AUTOSAR XML (schema 4-2-1)
standard types defined: float32, float64, sint8, sint16, sint32, uint8, uint16, uint32, boolean, dtRef_VOID, UInt8, Float32, Boolean, UInt32, SInt8
package /FoundationPkg/FoundationArchitecturePkg
  client server interface iElectricDriveControl
    operation enable
    operation getEnableState
      5 x arg, all with direction=OUT:
        state: type=tEnableState
        bridge1Health: type=tHealthStatus
        bridge2Health: type=tHealthStatus
        maxTimeCapability: type=tMaxTimeCapability
        redundancyLevel: type=tRedundancyLevel
    operation disable
  constant specification iTorqueChannelData_Channel{1..3}_Data_Init: value-spec={short-label=iTorqueChannelData_Channel{1..3}_Data_Init, fields=[0 Nm, 0]}
  sender receiver interface iTorqueChannelData
    data Channel{1..3}_Data: sw-calibration-access=READ-ONLY, type=tTorqueChannel, init-value=constant-reference=iTorqueChannelData_Channel{1..3}_Data_Init
  client server interface iElectricDrive
    5 x operation:
      setMotorTorqueDemand
        arg torque: type=tElectricMotorTorque, direction=IN
      getMotorTorqueEstimate
        arg torque: type=tElectricMotorTorque, direction=OUT
      getMotorMechanicalPosition
        arg position: type=tMechanicalMotorPosition, direction=OUT
      getMotorMechanicalVelocity
        arg velocity: type=tMechanicalMotorVelocity, direction=OUT
      getMotorTorqueDemand
        arg torque: type=tElectricMotorTorque, direction=OUT
  constant specification iAssistCapability_Capability_Init: value-spec={short-label=iAssistCapability_Capability_Init, fields=[0 %, 0 %]}
  sender receiver interface iAssistCapability
    data Capability: sw-calibration-access=READ-ONLY, type=tAssistCapability, init-value=constant-reference=iAssistCapability_Capability_Init
  constant specification iAssistTorque_AssistanceTorque_Init: value-spec={short-label=iAssistTorque_AssistanceTorque_Init, fields=[0 Nm, 0]}
  sender receiver interface iAssistTorque
    data AssistanceTorque: sw-calibration-access=READ-ONLY, type=tAssistTorque, init-value=constant-reference=iAssistTorque_AssistanceTorque_Init
  constant specification iVehicleData_VehicleSpeed_Init: value-spec={short-label=iVehicleData_VehicleSpeed_Init, fields=[0 Kph, 0, 0]}
  constant specification iVehicleData_EstimatedSteeringPosition_Init: value-spec={short-label=iVehicleData_EstimatedSteeringPosition_Init, fields=[0 deg, 0, 0 %]}
  constant specification iVehicleData_YawRate_Init: value-spec={short-label=iVehicleData_YawRate_Init, fields=[0 deg/S, 0]}
  sender receiver interface iVehicleData
    data VehicleSpeed: sw-calibration-access=READ-ONLY, type=tVehicleSpd, init-value=constant-reference=iVehicleData_VehicleSpeed_Init
    data EstimatedSteeringPosition: sw-calibration-access=READ-ONLY, type=tEstimatedSteeringPosition, init-value=constant-reference=iVehicleData_EstimatedSteeringPosition_Init
    data YawRate: sw-calibration-access=READ-ONLY, type=tYawRateData, init-value=constant-reference=iVehicleData_YawRate_Init
  constant specification iInputTorqueDemands_OverlayTorqueDemand_Init: value-spec={short-label=iInputTorqueDemands_OverlayTorqueDemand_Init, fields=[0 Nm, 0 Nm/s, 0, {short-label=tInputTorque_EQf_Init, fields=[1, 1, 1, 1]}]}
  constant specification iInputTorqueDemands_LimitingTorqueDemand_Init: value-spec={short-label=iInputTorqueDemands_LimitingTorqueDemand_Init, fields=[0 Nm, 0]}
  sender receiver interface iInputTorqueDemands
    data OverlayTorqueDemand: sw-calibration-access=READ-ONLY, type=tInputTorque, init-value=constant-reference=iInputTorqueDemands_OverlayTorqueDemand_Init
    data LimitingTorqueDemand: sw-calibration-access=READ-ONLY, type=tAssistTorque, init-value=constant-reference=iInputTorqueDemands_LimitingTorqueDemand_Init
package /FoundationPkg/FoundationArchitecturePkg/FoundationEpsAbstractionPkg
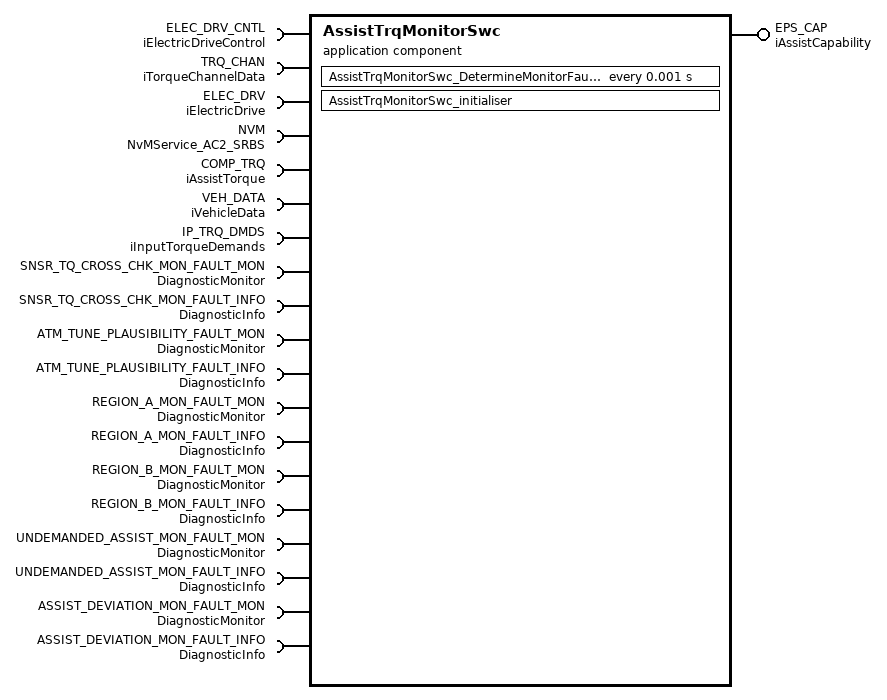
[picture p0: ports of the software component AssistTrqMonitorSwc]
  application sw component type AssistTrqMonitorSwc  # The AssistTrqMonitor reads the inputs and outputs of the main torque loop, and applies independent analysis of these signals in order to check that various ASIL D hazards are not present. If a hazard condition is detected the electric drive is disabled, and a fault is raised.
    4 x require port:
      ELEC_DRV_CNTL: required-interface=iElectricDriveControl
      TRQ_CHAN: required-interface=iTorqueChannelData  # The torque values read from each of the monitored channels
        required-com-specs:
          data-element=Channel{1..3}_Data, init-value=constant-reference=iTorqueChannelData_Channel{1..3}_Data_Init
      ELEC_DRV: required-interface=iElectricDrive
      NVM: required-interface=NvMService_AC2_SRBS  # Access to NVM
    provide port EPS_CAP: nonqueued-sender-com-spec{data-element=Capability, init-value=constant-reference=iAssistCapability_Capability_Init}, provided-interface=iAssistCapability  # The EPS assist capability, as a result of EPS diagnostic monitoring
    15 x require port:
      COMP_TRQ: nonqueued-receiver-com-spec{data-element=AssistanceTorque, init-value=constant-reference=iAssistTorque_AssistanceTorque_Init}, required-interface=iAssistTorque  # Compensated Torque input
      VEH_DATA: required-interface=iVehicleData  # Data regarding the vehicle dynamic state (speed, steering angle derived from the wheel speeds etc).
        required-com-specs:
          data-element=VehicleSpeed, init-value=constant-reference=iVehicleData_VehicleSpeed_Init
          data-element=EstimatedSteeringPosition, init-value=constant-reference=iVehicleData_EstimatedSteeringPosition_Init
          data-element=YawRate, init-value=constant-reference=iVehicleData_YawRate_Init
      IP_TRQ_DMDS: required-interface=iInputTorqueDemands
        required-com-specs:
          data-element=OverlayTorqueDemand, init-value=constant-reference=iInputTorqueDemands_OverlayTorqueDemand_Init
          data-element=LimitingTorqueDemand, init-value=constant-reference=iInputTorqueDemands_LimitingTorqueDemand_Init
      SNSR_TQ_CROSS_CHK_MON_FAULT_MON: required-interface=DiagnosticMonitor
      SNSR_TQ_CROSS_CHK_MON_FAULT_INFO: required-interface=DiagnosticInfo
      ATM_TUNE_PLAUSIBILITY_FAULT_MON: required-interface=DiagnosticMonitor
      ATM_TUNE_PLAUSIBILITY_FAULT_INFO: required-interface=DiagnosticInfo
      REGION_A_MON_FAULT_MON: required-interface=DiagnosticMonitor
      REGION_A_MON_FAULT_INFO: required-interface=DiagnosticInfo
      REGION_B_MON_FAULT_MON: required-interface=DiagnosticMonitor
      REGION_B_MON_FAULT_INFO: required-interface=DiagnosticInfo
      UNDEMANDED_ASSIST_MON_FAULT_MON: required-interface=DiagnosticMonitor
      UNDEMANDED_ASSIST_MON_FAULT_INFO: required-interface=DiagnosticInfo
      ASSIST_DEVIATION_MON_FAULT_MON: required-interface=DiagnosticMonitor
      ASSIST_DEVIATION_MON_FAULT_INFO: required-interface=DiagnosticInfo
    behavior AssistTrqMonitorSwc_IB: data-type-mapping=MappingSet, handle-termination-and-restart=NO-SUPPORT
      ar-typed-per-instance-memorys:
        data AssistTrqMonitorNvm: category=STRUCTURE, sw-calibration-access=READ-ONLY, type=tAssistTrqMonitorNvm
      timing event Event_DetermineMonitorFault: start-on-event=AssistTrqMonitorSwc_DetermineMonitorFault, period=0.001
      init event Event_initialiser_Init: start-on-event=AssistTrqMonitorSwc_initialiser
      implicit-inter-runnable-variables:
        data TunePlausibilityQf: sw-calibration-access=READ-ONLY, type=tQualityFactor, init-value=constant-reference=AssistTrqMonitorSwc_TunePlausibilityQf_Init  # This IRV is intended to inform the cyclic runnable that the plausibility fault is detected. In this case the cyclic runnable will set the capability to 0.
      per-instance-parameters:
        25 x parameter data prototype:
          ATM_COL_TQ_IDLE_THD: category=VALUE, sw-addr-method=VehicleTune, sw-calibration-access=READ-WRITE, type=Nm_0_0_to_2_0, init-value=constant-reference=VehicleTune_ATM_COL_TQ_IDLE_THD_Init  # Column Torque Idle Threshold
          ATM_UNDEMANDED_ASSI_SFTY_THD_MAP: category=ARRAY, sw-addr-method=VehicleTune, sw-calibration-access=READ-WRITE, type=tAtmUndemandedAssiSfbMap_0_0_to_255_0, init-value=constant-reference=VehicleTune_ATM_UNDEMANDED_ASSI_SFTY_THD_MAP_Init  # Assistance Torque Demand Safety Threshold for the detection of undemanded assist.
          ATM_ASSIST_CRV_MAP: category=ARRAY, sw-addr-method=VehicleTune, sw-calibration-access=READ-WRITE, type=tAtmAssistCrvMap_0_0_to_255_0, init-value=constant-reference=VehicleTune_ATM_ASSIST_CRV_MAP_Init  # Monitor Assist Curve Map which enables to determine the current assist torque capabilty with a certain additional Column Torque.
          ATM_ASSIST_CRV_MAP_BRKPTS: category=ARRAY, sw-addr-method=VehicleTune, sw-calibration-access=READ-WRITE, type=tAtmMonitorAssistCrvColTrqBpts_0_0_to_10_0, init-value=constant-reference=VehicleTune_ATM_ASSIST_CRV_MAP_BRKPTS_Init  # Column Torque Breakpoints for the Monitor Assist Curve Map.
          ATM_DRVR_TQ_SFTY_THD: category=VALUE, sw-addr-method=VehicleTune, sw-calibration-access=READ-WRITE, type=Nm_0_0_to_10_0, init-value=constant-reference=VehicleTune_ATM_DRVR_TQ_SFTY_THD_Init  # Driver Torque Safety Threshold
          ATM_DEB_RST_CNTR_THD: category=VALUE, sw-addr-method=VehicleTune, sw-calibration-access=READ-WRITE, type=ms_0_to_1000, init-value=constant-reference=VehicleTune_ATM_DEB_RST_CNTR_THD_Init  # Debounce Reset First Counter Threshold
          ATM_REGION_A_SFTY_THD_MAP: category=ARRAY, sw-addr-method=VehicleTune, sw-calibration-access=READ-WRITE, type=tAtmRegionASfbMap_0_0_to_255_0, init-value=constant-reference=VehicleTune_ATM_REGION_A_SFTY_THD_MAP_Init  # Region A Safety Threshold Map which provides an Assistance Torque Threshold above which a safety violation is detected.
          ATM_REGION_A_SFTY_THD_MAP_BRKPTS: category=ARRAY, sw-addr-method=VehicleTune, sw-calibration-access=READ-WRITE, type=tAtmRegionASfbMapBkpts_0_0_to_10_0, init-value=constant-reference=VehicleTune_ATM_REGION_A_SFTY_THD_MAP_BRKPTS_Init  # Column Torque Breakpoints for the Region A Safety Threshold Map.
          ATM_REGION_B_SFTY_THD_MAP: category=ARRAY, sw-addr-method=VehicleTune, sw-calibration-access=READ-WRITE, type=tAtmRegionBSfbMap_n255_0_to_255_0, init-value=constant-reference=VehicleTune_ATM_REGION_B_SFTY_THD_MAP_Init  # Region B Safety Threshold Map which provides an Assistance Torque Threshold above which a safety violation is detected.
          ATM_REGION_B_SFTY_THD_MAP_BRKPTS: category=ARRAY, sw-addr-method=VehicleTune, sw-calibration-access=READ-WRITE, type=tAtmRegionBSfbMapBkpts_0_0_to_10_0, init-value=constant-reference=VehicleTune_ATM_REGION_B_SFTY_THD_MAP_BRKPTS_Init  # Column Torque Breakpoints for the Region B Safety Threshold Map.
          ATM_SNSR_TQ_DE_THD: category=VALUE, sw-addr-method=VehicleTune, sw-calibration-access=READ-WRITE, type=Nm_0_0_to_10_0, init-value=constant-reference=VehicleTune_ATM_SNSR_TQ_DE_THD_Init  # Sensor Torque Deviation Threshold
          ATM_UNDEMANDED_TRIG_CNTR_THD: category=VALUE, sw-addr-method=VehicleTune, sw-calibration-access=READ-WRITE, type=ms_0_to_1000, init-value=constant-reference=VehicleTune_ATM_UNDEMANDED_TRIG_CNTR_THD_Init  # Debounce Counter for the undemanded assist fault Debouncer. If this failure situation is present for this duration the failure reaction will be triggered.
          ATM_VEH_SPD_BRKPTS: category=ARRAY, sw-addr-method=VehicleTune, sw-calibration-access=READ-WRITE, type=tAtmVehSpdMapBkpts_0_0_to_255_0, init-value=constant-reference=VehicleTune_ATM_VEH_SPD_BRKPTS_Init  # Vehicle Speed Breakpoints to be used for Assist Torque Monitor Safety Thresholds.
          ATM_ASSIST_DEVIATION_TRIG_CNTR_THD: category=VALUE, sw-addr-method=VehicleTune, sw-calibration-access=READ-WRITE, type=ms_0_to_1000, init-value=constant-reference=VehicleTune_ATM_ASSIST_DEVIATION_TRIG_CNTR_THD_Init  # Debounce Counter for the assist deviation fault debouncer. If this failure situation is present for this duration the failure reaction will be triggered.
          ATM_REGION_A_TRIG_CNTR_THD: category=VALUE, sw-addr-method=VehicleTune, sw-calibration-access=READ-WRITE, type=ms_0_to_1000, init-value=constant-reference=VehicleTune_ATM_REGION_A_TRIG_CNTR_THD_Init  # Debounce Counter for the region A fault debouncer. If this failure situation is present for this duration the failure reaction will be triggered.
          ATM_REGION_B_TRIG_CNTR_THD: category=VALUE, sw-addr-method=VehicleTune, sw-calibration-access=READ-WRITE, type=ms_0_to_1000, init-value=constant-reference=VehicleTune_ATM_REGION_B_TRIG_CNTR_THD_Init  # Debounce Counter for the region B fault debouncer. If this failure situation is present for this duration the failure reaction will be triggered.
          ATM_TQ_SNSR_ERR_TRIG_CNTR_THD: category=VALUE, sw-addr-method=VehicleTune, sw-calibration-access=READ-WRITE, type=ms_0_to_1000, init-value=constant-reference=VehicleTune_ATM_TQ_SNSR_ERR_TRIG_CNTR_THD_Init  # Debounce Counter for the torque sensor error fault debouncer. If this failure situation is present for this duration the failure reaction will be triggered.
          ATM_TQ_SNSR_CH_DE_TRIG_CNTR_THD: category=VALUE, sw-addr-method=VehicleTune, sw-calibration-access=READ-WRITE, type=ms_0_to_1000, init-value=constant-reference=VehicleTune_ATM_TQ_SNSR_CH_DE_TRIG_CNTR_THD_Init  # Debounce Counter for the torque sensor channel deviation fault debouncer. If this failure situation is present for this duration the failure reaction will be triggered.
          ATM_MAX_DEB_CNTR_VAL: category=VALUE, sw-addr-method=VehicleTune, sw-calibration-access=READ-WRITE, type=ms_0_to_1000, init-value=constant-reference=VehicleTune_ATM_MAX_DEB_CNTR_VAL_Init  # Maximum value of the ATM fault debounce counter
          ATM_DFT_VEH_SPD: category=VALUE, sw-addr-method=VehicleTune, sw-calibration-access=READ-WRITE, type=Kph_0_0_to_255_0, init-value=constant-reference=VehicleTune_ATM_DFT_VEH_SPD_Init  # ATM fallback vehicle speed to be used in case of unavailable filtered vehicle speed.
          ATM_RECIPR_GEAR_RATIO: category=VALUE, sw-addr-method=GearTune, sw-calibration-access=READ-WRITE, type=Float32_0_033_to_0_066, init-value=constant-reference=GearTune_ATM_RECIPR_GEAR_RATIO_Init  # Reciprocal Gear Ratio
          ATM_RECIPR_GEAR_EFFICIENCY: category=VALUE, sw-addr-method=GearTune, sw-calibration-access=READ-WRITE, type=Float32_1_0_to_2_0, init-value=constant-reference=GearTune_ATM_RECIPR_GEAR_EFFICIENCY_Init  # Reciprocal Gearbox Efficiency
          ATM_GEAR_POLARITY: category=VALUE, sw-addr-method=GearTune, sw-calibration-access=READ-WRITE, type=SInt8_n1_to_1, init-value=constant-reference=GearTune_ATM_GEAR_POLARITY_Init
          ATM_CHANNEL_HIGH_PRIORITY: category=ARRAY, sw-addr-method=SensorTune, sw-calibration-access=READ-WRITE, type=tTqSensChanHighPri, init-value=constant-reference=SensorTune_ATM_CHANNEL_HIGH_PRIORITY_Init  # Set which torque sensor channels are preferred during the torque calculation; some channels of the sensor can have cross chatter which disturbs the signal TRUE = High priority (preferable) FALSE = Low priority
          AssistTrqMonitorNvm_DEFAULT_VALUE: category=RECORD, type=tAssistTrqMonitorNvm, init-value=constant-reference=AssistTrqMonitorSwc_AssistTrqMonitorNvm_Init
      runnable AssistTrqMonitorSwc_DetermineMonitorFault: symbol=AssistTrqMonitor_DetermineMonitorFault  # Execute hazard detection functions for the controller torque assist path. Raise faults, disable electric drive and set zero EPS capability on fault detection. This is a diverse implementation of the main torque loop. It calculates Motor Torque Demand from the input torque signals, and then compares this with the Motor Torque Demand being requested by the main torque loop. The comparison must match within certain calibrated boundaries, and if not, a fault is raised and the motor drive is disabled. External torque demands which feed into the main loop, are compensated for by a torque signal which is subtracted from the requested Motor Torque Demand, before comparison.
        data-read-access:
          6 x access:
            R_TRQ_CHAN_Channel{1..3}_Data: accessed-variable=TRQ_CHAN.Channel{1..3}_Data
            R_COMP_TRQ_AssistanceTorque: accessed-variable=COMP_TRQ.AssistanceTorque
            R_VEH_DATA_VehicleSpeed: accessed-variable=VEH_DATA.VehicleSpeed
            R_IP_TRQ_DMDS_OverlayTorqueDemand: accessed-variable=IP_TRQ_DMDS.OverlayTorqueDemand
        data-write-access:
          access W_EPS_CAP_Capability: accessed-variable=EPS_CAP.Capability
        24 x parameter access:
          ATM_COL_TQ_IDLE_THD: accessed-parameter=ATM_COL_TQ_IDLE_THD
          ATM_DEB_RST_CNTR_THD: accessed-parameter=ATM_DEB_RST_CNTR_THD
          ATM_UNDEMANDED_TRIG_CNTR_THD: accessed-parameter=ATM_UNDEMANDED_TRIG_CNTR_THD
          ATM_ASSIST_CRV_MAP: accessed-parameter=ATM_ASSIST_CRV_MAP
          ATM_ASSIST_CRV_MAP_BRKPTS: accessed-parameter=ATM_ASSIST_CRV_MAP_BRKPTS
          ATM_DRVR_TQ_SFTY_THD: accessed-parameter=ATM_DRVR_TQ_SFTY_THD
          ATM_REGION_A_SFTY_THD_MAP: accessed-parameter=ATM_REGION_A_SFTY_THD_MAP
          ATM_REGION_A_SFTY_THD_MAP_BRKPTS: accessed-parameter=ATM_REGION_A_SFTY_THD_MAP_BRKPTS
          ATM_REGION_B_SFTY_THD_MAP: accessed-parameter=ATM_REGION_B_SFTY_THD_MAP
          ATM_REGION_B_SFTY_THD_MAP_BRKPTS: accessed-parameter=ATM_REGION_B_SFTY_THD_MAP_BRKPTS
          ATM_SNSR_TQ_DE_THD: accessed-parameter=ATM_SNSR_TQ_DE_THD
          ATM_UNDEMANDED_ASSI_SFTY_THD_MAP: accessed-parameter=ATM_UNDEMANDED_ASSI_SFTY_THD_MAP
          ATM_GEAR_POLARITY: accessed-parameter=ATM_GEAR_POLARITY
          ATM_RECIPR_GEAR_EFFICIENCY: accessed-parameter=ATM_RECIPR_GEAR_EFFICIENCY
          ATM_RECIPR_GEAR_RATIO: accessed-parameter=ATM_RECIPR_GEAR_RATIO
          ATM_VEH_SPD_BRKPTS: accessed-parameter=ATM_VEH_SPD_BRKPTS
          ATM_ASSIST_DEVIATION_TRIG_CNTR_THD: accessed-parameter=ATM_ASSIST_DEVIATION_TRIG_CNTR_THD
          ATM_REGION_A_TRIG_CNTR_THD: accessed-parameter=ATM_REGION_A_TRIG_CNTR_THD
          ATM_REGION_B_TRIG_CNTR_THD: accessed-parameter=ATM_REGION_B_TRIG_CNTR_THD
          ATM_TQ_SNSR_ERR_TRIG_CNTR_THD: accessed-parameter=ATM_TQ_SNSR_ERR_TRIG_CNTR_THD
          ATM_TQ_SNSR_CH_DE_TRIG_CNTR_THD: accessed-parameter=ATM_TQ_SNSR_CH_DE_TRIG_CNTR_THD
          ATM_MAX_DEB_CNTR_VAL: accessed-parameter=ATM_MAX_DEB_CNTR_VAL
          ATM_DFT_VEH_SPD: accessed-parameter=ATM_DFT_VEH_SPD
          ATM_CHANNEL_HIGH_PRIORITY: accessed-parameter=ATM_CHANNEL_HIGH_PRIORITY
        read-local-variables:
          access RV_TunePlausibilityQf: accessed-variable=TunePlausibilityQf
        23 x sync call, all with timeout=0:
          Call_ELEC_DRV_CNTL_disable: operation=ELEC_DRV_CNTL.disable
          Call_ELEC_DRV_getMotorTorqueDemand: operation=ELEC_DRV.getMotorTorqueDemand
          Call_REGION_A_MON_FAULT_SetEventStatus: operation=REGION_A_MON_FAULT_MON.SetEventStatus
          Call_REGION_A_MON_FAULT_ResetEventStatus: operation=REGION_A_MON_FAULT_MON.ResetEventDebounceStatus
          Call_REGION_A_MON_FAULT_GetEventStatus: operation=REGION_A_MON_FAULT_INFO.GetEventStatus
          Call_REGION_A_MON_FAULT_GetEventFailed: operation=REGION_A_MON_FAULT_INFO.GetEventFailed
          Call_REGION_B_MON_FAULT_SetEventStatus: operation=REGION_B_MON_FAULT_MON.SetEventStatus
          Call_REGION_B_MON_FAULT_ResetEventStatus: operation=REGION_B_MON_FAULT_MON.ResetEventDebounceStatus
          Call_REGION_B_MON_FAULT_GetEventStatus: operation=REGION_B_MON_FAULT_INFO.GetEventStatus
          Call_REGION_B_MON_FAULT_GetEventFailed: operation=REGION_B_MON_FAULT_INFO.GetEventFailed
          Call_ASSIST_DEVIATION_MON_FAULT_SetEventStatus: operation=ASSIST_DEVIATION_MON_FAULT_MON.SetEventStatus
          Call_ASSIST_DEVIATION_MON_FAULT_ResetEventStatus: operation=ASSIST_DEVIATION_MON_FAULT_MON.ResetEventDebounceStatus
          Call_ASSIST_DEVIATION_MON_FAULT_GetEventStatus: operation=ASSIST_DEVIATION_MON_FAULT_INFO.GetEventStatus
          Call_ASSIST_DEVIATION_MON_FAULT_GetEventFailed: operation=ASSIST_DEVIATION_MON_FAULT_INFO.GetEventFailed
          Call_UNDEMANDED_ASSIST_MON_FAULT_SetEventStatus: operation=UNDEMANDED_ASSIST_MON_FAULT_MON.SetEventStatus
          Call_UNDEMANDED_ASSIST_MON_FAULT_ResetEventStatus: operation=UNDEMANDED_ASSIST_MON_FAULT_MON.ResetEventDebounceStatus
          Call_UNDEMANDED_ASSIST_MON_FAULT_GetEventStatus: operation=UNDEMANDED_ASSIST_MON_FAULT_INFO.GetEventStatus
          Call_UNDEMANDED_ASSIST_MON_FAULT_GetEventFailed: operation=UNDEMANDED_ASSIST_MON_FAULT_INFO.GetEventFailed
          Call_NVM_SetRamBlockStatus: operation=NVM.SetRamBlockStatus
          Call_SNSR_TQ_CROSS_CHK_MON_FAULT_SetEventStatus: operation=SNSR_TQ_CROSS_CHK_MON_FAULT_MON.SetEventStatus
          Call_SNSR_TQ_CROSS_CHK_MON_FAULT_ResetEventStatus: operation=SNSR_TQ_CROSS_CHK_MON_FAULT_MON.ResetEventDebounceStatus
          Call_SNSR_TQ_CROSS_CHK_MON_FAULT_GetEventStatus: operation=SNSR_TQ_CROSS_CHK_MON_FAULT_INFO.GetEventStatus
          Call_SNSR_TQ_CROSS_CHK_MON_FAULT_GetEventFailed: operation=SNSR_TQ_CROSS_CHK_MON_FAULT_INFO.GetEventFailed
      runnable AssistTrqMonitorSwc_initialiser: symbol=AssistTrqMonitor_initialiser  # Checks plausibility of calibration data, raising fault and disabling electric drive on failure
        24 x parameter access:
          ATM_COL_TQ_IDLE_THD: accessed-parameter=ATM_COL_TQ_IDLE_THD
          ATM_DEB_RST_CNTR_THD: accessed-parameter=ATM_DEB_RST_CNTR_THD
          ATM_UNDEMANDED_TRIG_CNTR_THD: accessed-parameter=ATM_UNDEMANDED_TRIG_CNTR_THD
          ATM_ASSIST_CRV_MAP: accessed-parameter=ATM_ASSIST_CRV_MAP
          ATM_ASSIST_CRV_MAP_BRKPTS: accessed-parameter=ATM_ASSIST_CRV_MAP_BRKPTS
          ATM_DRVR_TQ_SFTY_THD: accessed-parameter=ATM_DRVR_TQ_SFTY_THD
          ATM_REGION_A_SFTY_THD_MAP: accessed-parameter=ATM_REGION_A_SFTY_THD_MAP
          ATM_REGION_A_SFTY_THD_MAP_BRKPTS: accessed-parameter=ATM_REGION_A_SFTY_THD_MAP_BRKPTS
          ATM_REGION_B_SFTY_THD_MAP: accessed-parameter=ATM_REGION_B_SFTY_THD_MAP
          ATM_REGION_B_SFTY_THD_MAP_BRKPTS: accessed-parameter=ATM_REGION_B_SFTY_THD_MAP_BRKPTS
          ATM_SNSR_TQ_DE_THD: accessed-parameter=ATM_SNSR_TQ_DE_THD
          ATM_UNDEMANDED_ASSI_SFTY_THD_MAP: accessed-parameter=ATM_UNDEMANDED_ASSI_SFTY_THD_MAP
          ATM_GEAR_POLARITY: accessed-parameter=ATM_GEAR_POLARITY
          ATM_RECIPR_GEAR_EFFICIENCY: accessed-parameter=ATM_RECIPR_GEAR_EFFICIENCY
          ATM_RECIPR_GEAR_RATIO: accessed-parameter=ATM_RECIPR_GEAR_RATIO
          ATM_VEH_SPD_BRKPTS: accessed-parameter=ATM_VEH_SPD_BRKPTS
          ATM_ASSIST_DEVIATION_TRIG_CNTR_THD: accessed-parameter=ATM_ASSIST_DEVIATION_TRIG_CNTR_THD
          ATM_REGION_B_TRIG_CNTR_THD: accessed-parameter=ATM_REGION_B_TRIG_CNTR_THD
          ATM_REGION_A_TRIG_CNTR_THD: accessed-parameter=ATM_REGION_A_TRIG_CNTR_THD
          ATM_DFT_VEH_SPD: accessed-parameter=ATM_DFT_VEH_SPD
          ATM_MAX_DEB_CNTR_VAL: accessed-parameter=ATM_MAX_DEB_CNTR_VAL
          ATM_TQ_SNSR_CH_DE_TRIG_CNTR_THD: accessed-parameter=ATM_TQ_SNSR_CH_DE_TRIG_CNTR_THD
          ATM_TQ_SNSR_ERR_TRIG_CNTR_THD: accessed-parameter=ATM_TQ_SNSR_ERR_TRIG_CNTR_THD
          ATM_CHANNEL_HIGH_PRIORITY: accessed-parameter=ATM_CHANNEL_HIGH_PRIORITY
        5 x sync call, all with timeout=0:
          Call_ELEC_DRV_CNTL_disable: operation=ELEC_DRV_CNTL.disable
          Call_ATM_TUNE_PLAUSIBILITY_FAULT_SetEventStatus: operation=ATM_TUNE_PLAUSIBILITY_FAULT_MON.SetEventStatus
          Call_ATM_TUNE_PLAUSIBILITY_FAULT_ResetEventStatus: operation=ATM_TUNE_PLAUSIBILITY_FAULT_MON.ResetEventDebounceStatus
          Call_ATM_TUNE_PLAUSIBILITY_FAULT_GetEventStatus: operation=ATM_TUNE_PLAUSIBILITY_FAULT_INFO.GetEventStatus
          Call_ATM_TUNE_PLAUSIBILITY_FAULT_GetEventFailed: operation=ATM_TUNE_PLAUSIBILITY_FAULT_INFO.GetEventFailed
        written-local-variables:
          access WV_TunePlausibilityQf: accessed-variable=TunePlausibilityQf
      13 x swc service dependency:
        SwcNv_AssistTrqMonitorNvm: assigned-ports=role-based-port-assignment={port-prototype=NVM, role=AssistTrqMonitorNvm}
          assigned-datas:
            role=ramBlock, used-data-element=AssistTrqMonitorNvm
            role=defaultValue, used-parameter-element=AssistTrqMonitorNvm_DEFAULT_VALUE
          service-needs:
            nv block needs SwcNv_AssistTrqMonitorNvm: calc-ram-block-crc=true, check-static-block-id=false, n-rom-blocks=1, ram-block-status-control=NV-RAM-MANAGER, readonly=false, reliability=ERROR-DETECTION, resistant-to-changed-sw=false, restore-at-start=true, store-at-shutdown=true, store-cyclic=false, store-emergency=false, store-immediate=false, use-auto-validation-at-shut-down=false, use-crc-comp-mechanism=true, write-only-once=false, write-verification=false
        Monitor_SNSR_TQ_CROSS_CHK_MON_FAULT: assigned-ports=role-based-port-assignment={port-prototype=SNSR_TQ_CROSS_CHK_MON_FAULT_MON, role=DiagnosticMonitor}
          service-needs:
            diagnostic event needs EventNeed_SNSR_TQ_CROSS_CHK_MON_FAULT
        Info_SNSR_TQ_CROSS_CHK_MON_FAULT: assigned-ports=role-based-port-assignment={port-prototype=SNSR_TQ_CROSS_CHK_MON_FAULT_INFO, role=DiagnosticInfo}
          service-needs:
            diagnostic event info needs InfoNeed_SNSR_TQ_CROSS_CHK_MON_FAULT
        Monitor_ATM_TUNE_PLAUSIBILITY_FAULT: assigned-ports=role-based-port-assignment={port-prototype=ATM_TUNE_PLAUSIBILITY_FAULT_MON, role=DiagnosticMonitor}
          service-needs:
            diagnostic event needs EventNeed_ATM_TUNE_PLAUSIBILITY_FAULT
        Info_ATM_TUNE_PLAUSIBILITY_FAULT: assigned-ports=role-based-port-assignment={port-prototype=ATM_TUNE_PLAUSIBILITY_FAULT_INFO, role=DiagnosticInfo}
          service-needs:
            diagnostic event info needs InfoNeed_ATM_TUNE_PLAUSIBILITY_FAULT
        Monitor_REGION_A_MON_FAULT: assigned-ports=role-based-port-assignment={port-prototype=REGION_A_MON_FAULT_MON, role=DiagnosticMonitor}
          service-needs:
            diagnostic event needs EventNeed_REGION_A_MON_FAULT
        Info_REGION_A_MON_FAULT: assigned-ports=role-based-port-assignment={port-prototype=REGION_A_MON_FAULT_INFO, role=DiagnosticInfo}
          service-needs:
            diagnostic event info needs InfoNeed_REGION_A_MON_FAULT
        Monitor_REGION_B_MON_FAULT: assigned-ports=role-based-port-assignment={port-prototype=REGION_B_MON_FAULT_MON, role=DiagnosticMonitor}
          service-needs:
            diagnostic event needs EventNeed_REGION_B_MON_FAULT
        Info_REGION_B_MON_FAULT: assigned-ports=role-based-port-assignment={port-prototype=REGION_B_MON_FAULT_INFO, role=DiagnosticInfo}
          service-needs:
            diagnostic event info needs InfoNeed_REGION_B_MON_FAULT
        Monitor_UNDEMANDED_ASSIST_MON_FAULT: assigned-ports=role-based-port-assignment={port-prototype=UNDEMANDED_ASSIST_MON_FAULT_MON, role=DiagnosticMonitor}
          service-needs:
            diagnostic event needs EventNeed_UNDEMANDED_ASSIST_MON_FAULT
        Info_UNDEMANDED_ASSIST_MON_FAULT: assigned-ports=role-based-port-assignment={port-prototype=UNDEMANDED_ASSIST_MON_FAULT_INFO, role=DiagnosticInfo}
          service-needs:
            diagnostic event info needs InfoNeed_UNDEMANDED_ASSIST_MON_FAULT
        Monitor_ASSIST_DEVIATION_MON_FAULT: assigned-ports=role-based-port-assignment={port-prototype=ASSIST_DEVIATION_MON_FAULT_MON, role=DiagnosticMonitor}
          service-needs:
            diagnostic event needs EventNeed_ASSIST_DEVIATION_MON_FAULT
        Info_ASSIST_DEVIATION_MON_FAULT: assigned-ports=role-based-port-assignment={port-prototype=ASSIST_DEVIATION_MON_FAULT_INFO, role=DiagnosticInfo}
          service-needs:
            diagnostic event info needs InfoNeed_ASSIST_DEVIATION_MON_FAULT
  impl type tAssistTrqMonitorNvm: category=STRUCTURE
    element SensedTorqueSaved: implementation-data-type=Nm
    element AssistTorqueDemandSaved: implementation-data-type=Nm
  26 x constant specification:
    AssistTrqMonitorSwc_TunePlausibilityQf_Init: value-spec=0
    VehicleTune_ATM_COL_TQ_IDLE_THD_Init: value-spec=0.2
    VehicleTune_ATM_UNDEMANDED_ASSI_SFTY_THD_MAP_Init: value-spec=[20.0, 20.0, 20.0, 20.0]
    VehicleTune_ATM_ASSIST_CRV_MAP_Init: value-spec=[[0.0, 0.485, 2.07, 3.57, 5.59, 10.35, 15.2, 122.45], [0.0, 0.485, 2.07, 3.57, 5.59, 10.35, 15.2, 122.45], [0.0, 0.485, 2.07, 3.57, 5.59, 10.35, 15.2, 122.45], [0.0, 0.485, 2.07, 3.57, 5.59, 10.35, 15.2, 122.45]]
    VehicleTune_ATM_ASSIST_CRV_MAP_BRKPTS_Init: value-spec=[0.0, 1.0, 2.0, 2.5, 2.8, 3.2, 3.5, 10.0]
    VehicleTune_ATM_DRVR_TQ_SFTY_THD_Init: value-spec=3.0
    VehicleTune_ATM_DEB_RST_CNTR_THD_Init: value-spec=10
    VehicleTune_ATM_REGION_A_SFTY_THD_MAP_Init: value-spec=[255.0, 255.0, 255.0]
    VehicleTune_ATM_REGION_A_SFTY_THD_MAP_BRKPTS_Init: value-spec=[2.0, 3.0, 4.0]
    VehicleTune_ATM_REGION_B_SFTY_THD_MAP_Init: value-spec=[-255.0, -255.0, -255.0]
    VehicleTune_ATM_REGION_B_SFTY_THD_MAP_BRKPTS_Init: value-spec=[3.0, 5.0, 7.0]
    VehicleTune_ATM_SNSR_TQ_DE_THD_Init: value-spec=0.5
    VehicleTune_ATM_UNDEMANDED_TRIG_CNTR_THD_Init: value-spec=40
    VehicleTune_ATM_VEH_SPD_BRKPTS_Init: value-spec=[0.0, 10.0, 50.0, 100.0]
    VehicleTune_ATM_ASSIST_DEVIATION_TRIG_CNTR_THD_Init: value-spec=40
    VehicleTune_ATM_REGION_A_TRIG_CNTR_THD_Init: value-spec=40
    VehicleTune_ATM_REGION_B_TRIG_CNTR_THD_Init: value-spec=40
    VehicleTune_ATM_TQ_SNSR_ERR_TRIG_CNTR_THD_Init: value-spec=40
    VehicleTune_ATM_TQ_SNSR_CH_DE_TRIG_CNTR_THD_Init: value-spec=40
    VehicleTune_ATM_MAX_DEB_CNTR_VAL_Init: value-spec=1000
    VehicleTune_ATM_DFT_VEH_SPD_Init: value-spec=0.0
    GearTune_ATM_RECIPR_GEAR_RATIO_Init: value-spec=0.0487805
    GearTune_ATM_RECIPR_GEAR_EFFICIENCY_Init: value-spec=1.1764706
    GearTune_ATM_GEAR_POLARITY_Init: value-spec=-1
    SensorTune_ATM_CHANNEL_HIGH_PRIORITY_Init: value-spec=[1, 0, 1]
    AssistTrqMonitorSwc_AssistTrqMonitorNvm_Init: value-spec={short-label=AssistTrqMonitorSwc_AssistTrqMonitorNvm_Init, fields=[0.0, 0.0]}
package /FoundationPkg/FoundationArchitecturePkg/FoundationEpsAbstractionPkg/ApplicationTypesPkg
  application record data type tAssistTrqMonitorNvm: category=STRUCTURE
    application record element SensedTorqueSaved: category=VALUE, type=Nm
    application record element AssistTorqueDemandSaved: category=VALUE, type=Nm_n255_0_to_255_0
package /FoundationPkg/FoundationArchitecturePkg/FoundationTypes
  impl type tEnableState: category=VALUE, base-type=sint32, compu {0=ES_DISABLE, 1=ES_NOT_READY, 2=ES_ENABLE, 3=ES_SHUTTING_DOWN}
  impl type tHealthStatus: category=VALUE, base-type=sint32, compu {0=HEALTH_NOT_CONFIGURED, 1=HEALTHY, 2=HEALTH_FAILED}
  impl type tMaxTimeCapability: category=VALUE, base-type=sint32, compu {0=TIME_30HRS, 1=TIME_11MIN, 2=TIME_10SEC, 3=TIME_UNLIMITED}
  impl type tRedundancyLevel: implementation-data-type=UInt8
  unit Nm_Unit: display-name=Nm
  impl type Nm: implementation-data-type=Float32
  compu method tQualityFactor_Compu: 0=QF_UNINITIALIZED, 0=QF_UNINITIALISED, 1=QF_UNAVAILABLE, 2=QF_DEGRADED, 3=QF_FULL
  impl type tQualityFactor: category=VALUE, base-type=sint32, compu-method=tQualityFactor_Compu
  impl type tTorqueChannel: category=STRUCTURE
    element Value: implementation-data-type=Nm
    element Qf: implementation-data-type=tQualityFactor
  impl type tElectricMotorTorque: category=STRUCTURE
    element Value: implementation-data-type=Nm
    element Qf: implementation-data-type=tQualityFactor
  unit Degrees_Unit: display-name=deg
  impl type Degrees: implementation-data-type=Float32
  impl type tExtendedQf: category=STRUCTURE
    4 x element, all with category=TYPE_REFERENCE:
      IntegrityDegraded: implementation-data-type=Boolean
      ResolutionDegraded: implementation-data-type=Boolean
      Defaulted: implementation-data-type=Boolean
      RedundancyLevel: implementation-data-type=tRedundancyLevel
  impl type tMechanicalMotorPosition: category=STRUCTURE
    element Value: implementation-data-type=Degrees
    element Qf: implementation-data-type=tQualityFactor
    element EQf: implementation-data-type=tExtendedQf
  unit DegreesPerSec_Unit: display-name=deg/S
  impl type DegreesPerSec: implementation-data-type=Float32
  impl type tMechanicalMotorVelocity: category=STRUCTURE
    element Value: implementation-data-type=DegreesPerSec
    element Qf: implementation-data-type=tQualityFactor
  unit Percent_Unit: display-name=%
  impl type Percent: implementation-data-type=Float32
  impl type tAssistCapability: category=STRUCTURE
    element Limit: implementation-data-type=Percent
    element Scale: implementation-data-type=Percent
  impl type tAssistTorque: category=STRUCTURE
    element Value: implementation-data-type=Nm
    element Qf: implementation-data-type=tQualityFactor
  unit Kph_Unit: display-name=Kph
  impl type Kph: implementation-data-type=Float32
  impl type tVehicleSpd: category=STRUCTURE
    element Filtered: implementation-data-type=Kph
    element Moving: implementation-data-type=Boolean
    element Qf: implementation-data-type=tQualityFactor
  impl type tEstimatedSteeringPosition: category=STRUCTURE
    element Value: implementation-data-type=Degrees
    element Qf: implementation-data-type=tQualityFactor
    element Confidence: implementation-data-type=Percent
  impl type tYawRateData: category=STRUCTURE
    element Value: implementation-data-type=DegreesPerSec
    element Qf: implementation-data-type=tQualityFactor
  unit NmPerSec_Unit: display-name=Nm/s
  impl type NmPerSec: implementation-data-type=Float32
  impl type tInputTorque: category=STRUCTURE
    4 x element, all with category=TYPE_REFERENCE:
      Value: implementation-data-type=Nm
      Derivative: implementation-data-type=NmPerSec
      Qf: implementation-data-type=tQualityFactor
      EQf: implementation-data-type=tExtendedQf
  impl type tAtmUndemandedAssiSfbMap: category=ARRAY
    element Element: array-size=4, array-size-semantics=FIXED-SIZE, implementation-data-type=Nm
  impl type tAtmMonitorAssistCrvColTrqBpts: category=ARRAY
    element Element: array-size=8, array-size-semantics=FIXED-SIZE, implementation-data-type=Nm
  impl type tAtmAssistCrvMap: category=ARRAY
    element Element: array-size=4, array-size-semantics=FIXED-SIZE, implementation-data-type=tAtmMonitorAssistCrvColTrqBpts
  unit ms_Unit: display-name=mS
  5 x impl type:
    ms: implementation-data-type=UInt32
    tAtmRegionASfbMap: category=ARRAY
      element Element: array-size=3, array-size-semantics=FIXED-SIZE, implementation-data-type=Nm
    tAtmRegionASfbMapBkpts: category=ARRAY
      element Element: array-size=3, array-size-semantics=FIXED-SIZE, implementation-data-type=Nm
    tAtmRegionBSfbMap: category=ARRAY
      element Element: array-size=3, array-size-semantics=FIXED-SIZE, implementation-data-type=Nm
    tAtmRegionBSfbMapBkpts: category=ARRAY
      element Element: array-size=3, array-size-semantics=FIXED-SIZE, implementation-data-type=Nm
  impl type tAtmVehSpdMapBkpts: category=ARRAY
    element Element: array-size=4, array-size-semantics=FIXED-SIZE, implementation-data-type=Kph
  impl type tTqSensChanHighPri: category=ARRAY
    element Element: array-size=3, array-size-semantics=FIXED-SIZE, implementation-data-type=Boolean
package /FoundationPkg/FoundationArchitecturePkg/FoundationTypes/ApplicationTypesPkg
  8 x app type, all with category=VALUE:
    tEnableState: base-type=sint32, compu {0=ES_DISABLE, 1=ES_NOT_READY, 2=ES_ENABLE, 3=ES_SHUTTING_DOWN}  # EPP Abstraction status
    tHealthStatus: base-type=sint32, compu {0=HEALTH_NOT_CONFIGURED, 1=HEALTHY, 2=HEALTH_FAILED}  # Indication of the health status of an element of the system.
    tMaxTimeCapability: base-type=sint32, compu {0=TIME_30HRS, 1=TIME_11MIN, 2=TIME_10SEC, 3=TIME_UNLIMITED}  # Indication of the time an element of the system can continue to function within its defined operating parameters. This definition is used to allow elements to report there remaining safe life-span in the event of a failure.
    tRedundancyLevel: range phys 1..7  # Type used for attributes indicating a level of redundancy of some signal. i.e. could be used to indicate the number of failures required before the signal would become degraded in some way. Thus : 1 : degradation of the signal upon next failure 2 : degradation of the signal upon next 2 failures 3 : degradation of the signal upon next 3 failures and so on.
    UInt8
    Nm: compu {phys=raw for raw -10..10; unit Nm}, range phys -10..10, unit=Nm
    Float32
    tQualityFactor: base-type=sint32, compu-method=tQualityFactor_Compu  # Describes the quality of an input signal.
  application record data type tTorqueChannel: category=STRUCTURE  # Used for an individual torque channel signal
    application record element Value: category=VALUE, type=Nm
    application record element Qf: category=VALUE, type=tQualityFactor
  application record data type tElectricMotorTorque: category=STRUCTURE
    application record element Value: category=VALUE, type=Nm
    application record element Qf: category=VALUE, type=tQualityFactor
  app type Degrees_n29520_to_29520: category=VALUE, compu {phys=raw for raw -29520..29520; unit deg}, range phys -29520..29520, unit=deg
  app type Boolean: category=VALUE
  application record data type tExtendedQf: category=STRUCTURE  # Extended quality information for a signal, used in conjunction with tQualityFactor. Legal combinations are: Qf = QF_UNINITIALISED, QF_UNINITIALIZED: eQf should be ignored. Qf = QF_UNAVAILABLE: eQf should be ignored. Qf = QF_DEGRADED: eQf - may have any combination of LossOfIntegrity, ResolutionDegraded or Defaulted set to True, and any Redundancy Level. Qf = QF_FULL: eQf Redundancy Level is the only parameter which may be used (LossOfIntegrity, ResolutionDegraded, Defaulted to be ignored).
    4 x application record element, all with category=VALUE:
      IntegrityDegraded: type=Boolean
      ResolutionDegraded: type=Boolean
      Defaulted: type=Boolean
      RedundancyLevel: type=tRedundancyLevel
  application record data type tMechanicalMotorPosition: category=STRUCTURE
    application record element Value: category=VALUE, type=Degrees_n29520_to_29520
    application record element Qf: category=VALUE, type=tQualityFactor
    application record element EQf: category=STRUCTURE, type=tExtendedQf
  app type Degrees: category=VALUE, compu {phys=raw for raw -INF..INF; unit deg}, unit=deg
  app type DegreesPerSec_n47970_to_47970: category=VALUE, compu {phys=raw for raw -47970..47970; unit deg/S}, range phys -47970..47970, unit=deg/S
  application record data type tMechanicalMotorVelocity: category=STRUCTURE
    application record element Value: category=VALUE, type=DegreesPerSec_n47970_to_47970
    application record element Qf: category=VALUE, type=tQualityFactor
  app type DegreesPerSec: category=VALUE, compu {phys=raw for raw -INF..INF; unit deg/S}, unit=deg/S
  app type Percent: category=VALUE, compu {phys=raw for raw 0..100; unit %}, range phys 0..100, unit=%
  application record data type tAssistCapability: category=STRUCTURE
    application record element Limit: category=VALUE, type=Percent
    application record element Scale: category=VALUE, type=Percent
  app type Nm_n255_0_to_255_0: category=VALUE, compu {phys=raw for raw -255..255; unit Nm}, range phys -255..255, unit=Nm
  application record data type tAssistTorque: category=STRUCTURE
    application record element Value: category=VALUE, type=Nm_n255_0_to_255_0
    application record element Qf: category=VALUE, type=tQualityFactor
  app type Kph_0_to_400: category=VALUE, compu {phys=raw for raw 0..400; unit Kph}, range phys 0..400, unit=Kph
  application record data type tVehicleSpd: category=STRUCTURE
    application record element Filtered: category=VALUE, type=Kph_0_to_400
    application record element Moving: category=VALUE, type=Boolean
    application record element Qf: category=VALUE, type=tQualityFactor
  app type Kph: category=VALUE, compu {phys=raw for raw -INF..INF; unit Kph}, unit=Kph
  app type Degrees_n720_0_to_720_0: category=VALUE, compu {phys=raw for raw -720..720; unit deg}, range phys -720..720, unit=deg
  application record data type tEstimatedSteeringPosition: category=STRUCTURE
    application record element Value: category=VALUE, type=Degrees_n720_0_to_720_0
    application record element Qf: category=VALUE, type=tQualityFactor
    application record element Confidence: category=VALUE, type=Percent
  application record data type tYawRateData: category=STRUCTURE
    application record element Value: category=VALUE, type=DegreesPerSec
    application record element Qf: category=VALUE, type=tQualityFactor
  app type NmPerSec: category=VALUE, compu {phys=raw for raw -2048..2048; unit Nm/s}, range phys -2048..2048, unit=Nm/s  # Rate of change of torque
  application record data type tInputTorque: category=STRUCTURE
    4 x application record element:
      Value: category=VALUE, type=Nm
      Derivative: category=VALUE, type=NmPerSec
      Qf: category=VALUE, type=tQualityFactor
      EQf: category=STRUCTURE, type=tExtendedQf
  app type Nm_0_0_to_2_0: category=VALUE, compu {phys=raw for raw 0..2; unit Nm}, range phys 0..2, unit=Nm
  app type Nm_0_0_to_255_0: category=VALUE, compu {phys=raw for raw 0..255; unit Nm}, range phys 0..255, unit=Nm
  4 x application array data type, all with category=ARRAY:
    tAtmUndemandedAssiSfbMap_0_0_to_255_0  # Used to define Undemanded Assist SFB Map
      element Element: category=VALUE, type=Nm_0_0_to_255_0, array-size-semantics=FIXED-SIZE, max-number-of-elements=4
    tAtmMonitorAssistCrvColTrqBpts_0_0_to_255_0  # Used to define Column Torque Breakpoints for the Monitor Assist Curve Map.
      element Element: category=VALUE, type=Nm_0_0_to_255_0, array-size-semantics=FIXED-SIZE, max-number-of-elements=8
    tAtmAssistCrvMap_0_0_to_255_0  # Used to define ATM Monitor Assist Curve Map
      element Element: category=ARRAY, type=tAtmMonitorAssistCrvColTrqBpts_0_0_to_255_0, array-size-semantics=FIXED-SIZE, max-number-of-elements=4
    tAtmMonitorAssistCrvColTrqBpts  # Used to define Column Torque Breakpoints for the Monitor Assist Curve Map.
      element Element: category=VALUE, type=Nm, array-size-semantics=FIXED-SIZE, max-number-of-elements=8
  app type Nm_0_0_to_10_0: category=VALUE, compu {phys=raw for raw 0..10; unit Nm}, range phys 0..10, unit=Nm
  application array data type tAtmMonitorAssistCrvColTrqBpts_0_0_to_10_0: category=ARRAY  # Used to define Column Torque Breakpoints for the Monitor Assist Curve Map.
    element Element: category=VALUE, type=Nm_0_0_to_10_0, array-size-semantics=FIXED-SIZE, max-number-of-elements=8
  app type ms_0_to_1000: category=VALUE, compu {phys=raw for raw 0..1000; unit mS}, range phys 0..1000, unit=mS
  app type UInt32: category=VALUE
  4 x application array data type, all with category=ARRAY:
    tAtmRegionASfbMap_0_0_to_255_0  # Used to define ATM Region A SFB Map
      element Element: category=VALUE, type=Nm_0_0_to_255_0, array-size-semantics=FIXED-SIZE, max-number-of-elements=3
    tAtmRegionASfbMapBkpts_0_0_to_10_0  # Used to define ATM Region A SFB Map Breakpoints
      element Element: category=VALUE, type=Nm_0_0_to_10_0, array-size-semantics=FIXED-SIZE, max-number-of-elements=3
    tAtmRegionBSfbMap_n255_0_to_255_0  # Used to define Region B SFB Map
      element Element: category=VALUE, type=Nm_n255_0_to_255_0, array-size-semantics=FIXED-SIZE, max-number-of-elements=3
    tAtmRegionBSfbMapBkpts_0_0_to_10_0  # Used to define ATM Region B SFB Map Breakpoints
      element Element: category=VALUE, type=Nm_0_0_to_10_0, array-size-semantics=FIXED-SIZE, max-number-of-elements=3
  app type Kph_0_0_to_255_0: category=VALUE, compu {phys=raw for raw 0..255; unit Kph}, range phys 0..255, unit=Kph
  application array data type tAtmVehSpdMapBkpts_0_0_to_255_0: category=ARRAY  # Used to define ATM Vehicle Speed Map Breakpoints
    element Element: category=VALUE, type=Kph_0_0_to_255_0, array-size-semantics=FIXED-SIZE, max-number-of-elements=4
  app type Float32_0_033_to_0_066: category=VALUE, range phys 0.033..0.066
  app type Float32_1_0_to_2_0: category=VALUE, range phys 1..2
  app type SInt8_n1_to_1: category=VALUE, range phys -1..1
  application array data type tTqSensChanHighPri: category=ARRAY  # Map of Torque Sensor channel high priority settings
    element Element: category=VALUE, type=Boolean, array-size-semantics=FIXED-SIZE, max-number-of-elements=3
package /DataTypeMappingSets
  data type mapping set MappingSet
    data-type-maps:
      application-data-type=tEnableState, implementation-data-type=tEnableState
      application-data-type=tHealthStatus, implementation-data-type=tHealthStatus
      application-data-type=tMaxTimeCapability, implementation-data-type=tMaxTimeCapability
      application-data-type=UInt8, implementation-data-type=UInt8
      application-data-type=tRedundancyLevel, implementation-data-type=tRedundancyLevel
      application-data-type=Float32, implementation-data-type=Float32
      application-data-type=Nm, implementation-data-type=Nm
      application-data-type=tQualityFactor, implementation-data-type=tQualityFactor
      application-data-type=tTorqueChannel, implementation-data-type=tTorqueChannel
      application-data-type=tElectricMotorTorque, implementation-data-type=tElectricMotorTorque
      application-data-type=Degrees_n29520_to_29520, implementation-data-type=Degrees
      application-data-type=Boolean, implementation-data-type=Boolean
      application-data-type=tExtendedQf, implementation-data-type=tExtendedQf
      application-data-type=Degrees, implementation-data-type=Degrees
      application-data-type=tMechanicalMotorPosition, implementation-data-type=tMechanicalMotorPosition
      application-data-type=DegreesPerSec_n47970_to_47970, implementation-data-type=DegreesPerSec
      application-data-type=DegreesPerSec, implementation-data-type=DegreesPerSec
      application-data-type=tMechanicalMotorVelocity, implementation-data-type=tMechanicalMotorVelocity
      application-data-type=Percent, implementation-data-type=Percent
      application-data-type=tAssistCapability, implementation-data-type=tAssistCapability
      application-data-type=Nm_n255_0_to_255_0, implementation-data-type=Nm
      application-data-type=tAssistTorque, implementation-data-type=tAssistTorque
      application-data-type=Kph_0_to_400, implementation-data-type=Kph
      application-data-type=Kph, implementation-data-type=Kph
      application-data-type=tVehicleSpd, implementation-data-type=tVehicleSpd
      application-data-type=Degrees_n720_0_to_720_0, implementation-data-type=Degrees
      application-data-type=tEstimatedSteeringPosition, implementation-data-type=tEstimatedSteeringPosition
      application-data-type=tYawRateData, implementation-data-type=tYawRateData
      application-data-type=NmPerSec, implementation-data-type=NmPerSec
      application-data-type=tInputTorque, implementation-data-type=tInputTorque
      application-data-type=tAssistTrqMonitorNvm, implementation-data-type=tAssistTrqMonitorNvm
      application-data-type=Nm_0_0_to_2_0, implementation-data-type=Nm
      application-data-type=Nm_0_0_to_255_0, implementation-data-type=Nm
      application-data-type=tAtmUndemandedAssiSfbMap_0_0_to_255_0, implementation-data-type=tAtmUndemandedAssiSfbMap
      application-data-type=tAtmMonitorAssistCrvColTrqBpts_0_0_to_255_0, implementation-data-type=tAtmMonitorAssistCrvColTrqBpts
      application-data-type=tAtmMonitorAssistCrvColTrqBpts, implementation-data-type=tAtmMonitorAssistCrvColTrqBpts
      application-data-type=tAtmAssistCrvMap_0_0_to_255_0, implementation-data-type=tAtmAssistCrvMap
      application-data-type=Nm_0_0_to_10_0, implementation-data-type=Nm
      application-data-type=tAtmMonitorAssistCrvColTrqBpts_0_0_to_10_0, implementation-data-type=tAtmMonitorAssistCrvColTrqBpts
      application-data-type=UInt32, implementation-data-type=UInt32
      application-data-type=ms_0_to_1000, implementation-data-type=ms
      application-data-type=tAtmRegionASfbMap_0_0_to_255_0, implementation-data-type=tAtmRegionASfbMap
      application-data-type=tAtmRegionASfbMapBkpts_0_0_to_10_0, implementation-data-type=tAtmRegionASfbMapBkpts
      application-data-type=tAtmRegionBSfbMap_n255_0_to_255_0, implementation-data-type=tAtmRegionBSfbMap
      application-data-type=tAtmRegionBSfbMapBkpts_0_0_to_10_0, implementation-data-type=tAtmRegionBSfbMapBkpts
      application-data-type=Kph_0_0_to_255_0, implementation-data-type=Kph
      application-data-type=tAtmVehSpdMapBkpts_0_0_to_255_0, implementation-data-type=tAtmVehSpdMapBkpts
      application-data-type=Float32_0_033_to_0_066, implementation-data-type=Float32
      application-data-type=Float32_1_0_to_2_0, implementation-data-type=Float32
      application-data-type=SInt8_n1_to_1, implementation-data-type=SInt8
      application-data-type=tTqSensChanHighPri, implementation-data-type=tTqSensChanHighPri
package /SwAddrMethods
  8 x sw addr method, all with memory-allocation-keyword-policy=ADDR-METHOD-SHORT-NAME, section-type=CALIBRATION-ONLINE:
    VehicleTune
    PlatformTune
    DevelopmentTune
    SteeringTune
    SensorTune
    EppTune
    GearTune
    FeatureTune
package /Predefined_DEV/ImplementationDataTypes
  impl type NvM_RequestResultType: compu {0=NVM_REQ_OK, 1=NVM_REQ_NOT_OK, 2=NVM_REQ_PENDING, 3=NVM_REQ_INTEGRITY_FAILED, 4=NVM_REQ_BLOCK_SKIPPED, 5=NVM_REQ_NV_INVALIDATED, 6=NVM_REQ_CANCELED, 7=NVM_REQ_REDUNDANCY_FAILED, 8=NVM_REQ_RESTORED_FROM_ROM}, implementation-data-type=uint8
package /Predefined_DEV/PortInterfaces
  client server interface NvMService_AC2_SRBS: is-service=true
    operation GetErrorStatus: possible-error=NvMService_AC2_SRBS/E_NOT_OK
      arg ErrorStatus: type=NvM_RequestResultType, direction=OUT, server-argument-impl-policy=USE-ARGUMENT-TYPE
    operation SetRamBlockStatus: possible-error=NvMService_AC2_SRBS/E_NOT_OK
      arg RamBlockStatus: type=boolean, direction=IN, server-argument-impl-policy=USE-ARGUMENT-TYPE
    error E_NOT_OK: error-code=1
package /MICROSAR/Dem_swc/DataTypes
  18 x impl type:
    Dem_EventIdType: range raw 1..65535, implementation-data-type=uint16
    Dem_RatioIdType: range raw 1..65535, implementation-data-type=uint16
    Dem_DTCStatusMaskType: range raw 0..255, implementation-data-type=uint8
    Dem_OperationCycleIdType: range raw 0..255, implementation-data-type=uint8
    Dem_DTCGroupType: range raw 0..16777215, implementation-data-type=uint32
    Dem_MaxDataValueType: category=ARRAY, sw-calibration-access=READ-ONLY
      element Dem_MaxDataValueTypeElement: array-size=1, array-size-semantics=FIXED-SIZE, implementation-data-type=uint8
    Dem_EventStatusType: compu {0=DEM_EVENT_STATUS_PASSED, 1=DEM_EVENT_STATUS_FAILED, 2=DEM_EVENT_STATUS_PREPASSED, 3=DEM_EVENT_STATUS_PREFAILED}, implementation-data-type=uint8
    Dem_EventStatusExtendedType: compu {1=DEM_UDS_STATUS_TF, 2=DEM_UDS_STATUS_TFTOC, 4=DEM_UDS_STATUS_PDTC, 8=DEM_UDS_STATUS_CDTC, 16=DEM_UDS_STATUS_TNCSLC, 32=DEM_UDS_STATUS_TFSLC, 64=DEM_UDS_STATUS_TNCTOC, 128=DEM_UDS_STATUS_WIR}, implementation-data-type=uint8
    Dem_InitMonitorReasonType: compu {1=DEM_INIT_MONITOR_CLEAR, 2=DEM_INIT_MONITOR_RESTART, 3=DEM_INIT_MONITOR_REENABLED, 4=DEM_INIT_MONITOR_STORAGE_REENABLED}, implementation-data-type=uint8
    Dem_DTCOriginType: compu {1=DEM_DTC_ORIGIN_PRIMARY_MEMORY, 2=DEM_DTC_ORIGIN_MIRROR_MEMORY, 3=DEM_DTC_ORIGIN_PERMANENT_MEMORY, 4=DEM_DTC_ORIGIN_SECONDARY_MEMORY, 4=DEM_DTC_ORIGIN_USERDEFINED_MEMORY_10, 4=DEM_DTC_ORIGIN_USERDEFINED_MEMORY_11, 4=DEM_DTC_ORIGIN_USERDEFINED_MEMORY_12, 4=DEM_DTC_ORIGIN_USERDEFINED_MEMORY_13, 4=DEM_DTC_ORIGIN_USERDEFINED_MEMORY_14, 4=DEM_DTC_ORIGIN_USERDEFINED_MEMORY_15, 4=DEM_DTC_ORIGIN_USERDEFINED_MEMORY_16, 4=DEM_DTC_ORIGIN_USERDEFINED_MEMORY_17, 4=DEM_DTC_ORIGIN_USERDEFINED_MEMORY_18, 4=DEM_DTC_ORIGIN_USERDEFINED_MEMORY_19, 4=DEM_DTC_ORIGIN_USERDEFINED_MEMORY_1A, 4=DEM_DTC_ORIGIN_USERDEFINED_MEMORY_1B, 4=DEM_DTC_ORIGIN_USERDEFINED_MEMORY_1C, 4=DEM_DTC_ORIGIN_USERDEFINED_MEMORY_1D, 4=DEM_DTC_ORIGIN_USERDEFINED_MEMORY_1E, 4=DEM_DTC_ORIGIN_USERDEFINED_MEMORY_1F, 4=DEM_DTC_ORIGIN_USERDEFINED_MEMORY_20, 4=DEM_DTC_ORIGIN_USERDEFINED_MEMORY_21, 4=DEM_DTC_ORIGIN_USERDEFINED_MEMORY_22, 4=DEM_DTC_ORIGIN_USERDEFINED_MEMORY_23, 4=DEM_DTC_ORIGIN_USERDEFINED_MEMORY_24, 4=DEM_DTC_ORIGIN_USERDEFINED_MEMORY_25, 4=DEM_DTC_ORIGIN_USERDEFINED_MEMORY_26, 4=DEM_DTC_ORIGIN_USERDEFINED_MEMORY_27, 4=DEM_DTC_ORIGIN_USERDEFINED_MEMORY_28, 4=DEM_DTC_ORIGIN_USERDEFINED_MEMORY_29, 4=DEM_DTC_ORIGIN_USERDEFINED_MEMORY_2A, 4=DEM_DTC_ORIGIN_USERDEFINED_MEMORY_2B, 4=DEM_DTC_ORIGIN_USERDEFINED_MEMORY_2C, 4=DEM_DTC_ORIGIN_USERDEFINED_MEMORY_2D, 4=DEM_DTC_ORIGIN_USERDEFINED_MEMORY_2E, 4=DEM_DTC_ORIGIN_USERDEFINED_MEMORY_2F, 4=DEM_DTC_ORIGIN_USERDEFINED_MEMORY_30, 4=DEM_DTC_ORIGIN_USERDEFINED_MEMORY_31, 4=DEM_DTC_ORIGIN_USERDEFINED_MEMORY_32, 4=DEM_DTC_ORIGIN_USERDEFINED_MEMORY_33, 4=DEM_DTC_ORIGIN_USERDEFINED_MEMORY_34, 4=DEM_DTC_ORIGIN_USERDEFINED_MEMORY_35, 4=DEM_DTC_ORIGIN_USERDEFINED_MEMORY_36, 4=DEM_DTC_ORIGIN_USERDEFINED_MEMORY_37, 4=DEM_DTC_ORIGIN_USERDEFINED_MEMORY_38, 4=DEM_DTC_ORIGIN_USERDEFINED_MEMORY_39, 4=DEM_DTC_ORIGIN_USERDEFINED_MEMORY_3A, 4=DEM_DTC_ORIGIN_USERDEFINED_MEMORY_3B, 4=DEM_DTC_ORIGIN_USERDEFINED_MEMORY_3C, 4=DEM_DTC_ORIGIN_USERDEFINED_MEMORY_3D, 4=DEM_DTC_ORIGIN_USERDEFINED_MEMORY_3E, 4=DEM_DTC_ORIGIN_USERDEFINED_MEMORY_3F, 4=DEM_DTC_ORIGIN_USERDEFINED_MEMORY_40, 4=DEM_DTC_ORIGIN_USERDEFINED_MEMORY_41, 4=DEM_DTC_ORIGIN_USERDEFINED_MEMORY_42, 4=DEM_DTC_ORIGIN_USERDEFINED_MEMORY_43, 4=DEM_DTC_ORIGIN_USERDEFINED_MEMORY_44, 4=DEM_DTC_ORIGIN_USERDEFINED_MEMORY_45, 4=DEM_DTC_ORIGIN_USERDEFINED_MEMORY_46, 4=DEM_DTC_ORIGIN_USERDEFINED_MEMORY_47, 4=DEM_DTC_ORIGIN_USERDEFINED_MEMORY_48, 4=DEM_DTC_ORIGIN_USERDEFINED_MEMORY_49, 4=DEM_DTC_ORIGIN_USERDEFINED_MEMORY_4A, 4=DEM_DTC_ORIGIN_USERDEFINED_MEMORY_4B, 4=DEM_DTC_ORIGIN_USERDEFINED_MEMORY_4C, 4=DEM_DTC_ORIGIN_USERDEFINED_MEMORY_4D, 4=DEM_DTC_ORIGIN_USERDEFINED_MEMORY_4E, 4=DEM_DTC_ORIGIN_USERDEFINED_MEMORY_4F, 4=DEM_DTC_ORIGIN_USERDEFINED_MEMORY_50, 4=DEM_DTC_ORIGIN_USERDEFINED_MEMORY_51, 4=DEM_DTC_ORIGIN_USERDEFINED_MEMORY_52, 4=DEM_DTC_ORIGIN_USERDEFINED_MEMORY_53, 4=DEM_DTC_ORIGIN_USERDEFINED_MEMORY_54, 4=DEM_DTC_ORIGIN_USERDEFINED_MEMORY_55, 4=DEM_DTC_ORIGIN_USERDEFINED_MEMORY_56, 4=DEM_DTC_ORIGIN_USERDEFINED_MEMORY_57, 4=DEM_DTC_ORIGIN_USERDEFINED_MEMORY_58, 4=DEM_DTC_ORIGIN_USERDEFINED_MEMORY_59, 4=DEM_DTC_ORIGIN_USERDEFINED_MEMORY_5A, 4=DEM_DTC_ORIGIN_USERDEFINED_MEMORY_5B, 4=DEM_DTC_ORIGIN_USERDEFINED_MEMORY_5C, 4=DEM_DTC_ORIGIN_USERDEFINED_MEMORY_5D, 4=DEM_DTC_ORIGIN_USERDEFINED_MEMORY_5E, 4=DEM_DTC_ORIGIN_USERDEFINED_MEMORY_5F, 4=DEM_DTC_ORIGIN_USERDEFINED_MEMORY_60, 4=DEM_DTC_ORIGIN_USERDEFINED_MEMORY_61, 4=DEM_DTC_ORIGIN_USERDEFINED_MEMORY_62, 4=DEM_DTC_ORIGIN_USERDEFINED_MEMORY_63, 4=DEM_DTC_ORIGIN_USERDEFINED_MEMORY_64, 4=DEM_DTC_ORIGIN_USERDEFINED_MEMORY_65, 4=DEM_DTC_ORIGIN_USERDEFINED_MEMORY_66, 4=DEM_DTC_ORIGIN_USERDEFINED_MEMORY_67, 4=DEM_DTC_ORIGIN_USERDEFINED_MEMORY_68, 4=DEM_DTC_ORIGIN_USERDEFINED_MEMORY_69, 4=DEM_DTC_ORIGIN_USERDEFINED_MEMORY_6A, 4=DEM_DTC_ORIGIN_USERDEFINED_MEMORY_6B, 4=DEM_DTC_ORIGIN_USERDEFINED_MEMORY_6C, 4=DEM_DTC_ORIGIN_USERDEFINED_MEMORY_6D, 4=DEM_DTC_ORIGIN_USERDEFINED_MEMORY_6E, 4=DEM_DTC_ORIGIN_USERDEFINED_MEMORY_6F, 4=DEM_DTC_ORIGIN_USERDEFINED_MEMORY_70, 4=DEM_DTC_ORIGIN_USERDEFINED_MEMORY_71, 4=DEM_DTC_ORIGIN_USERDEFINED_MEMORY_72, 4=DEM_DTC_ORIGIN_USERDEFINED_MEMORY_73, 4=DEM_DTC_ORIGIN_USERDEFINED_MEMORY_74, 4=DEM_DTC_ORIGIN_USERDEFINED_MEMORY_75, 4=DEM_DTC_ORIGIN_USERDEFINED_MEMORY_76, 4=DEM_DTC_ORIGIN_USERDEFINED_MEMORY_77, 4=DEM_DTC_ORIGIN_USERDEFINED_MEMORY_78, 4=DEM_DTC_ORIGIN_USERDEFINED_MEMORY_79, 4=DEM_DTC_ORIGIN_USERDEFINED_MEMORY_7A, 4=DEM_DTC_ORIGIN_USERDEFINED_MEMORY_7B, 4=DEM_DTC_ORIGIN_USERDEFINED_MEMORY_7C, 4=DEM_DTC_ORIGIN_USERDEFINED_MEMORY_7D, 4=DEM_DTC_ORIGIN_USERDEFINED_MEMORY_7E, 4=DEM_DTC_ORIGIN_USERDEFINED_MEMORY_7F, 4=DEM_DTC_ORIGIN_USERDEFINED_MEMORY_80, 4=DEM_DTC_ORIGIN_USERDEFINED_MEMORY_81, 4=DEM_DTC_ORIGIN_USERDEFINED_MEMORY_82, 4=DEM_DTC_ORIGIN_USERDEFINED_MEMORY_83, 4=DEM_DTC_ORIGIN_USERDEFINED_MEMORY_84, 4=DEM_DTC_ORIGIN_USERDEFINED_MEMORY_85, 4=DEM_DTC_ORIGIN_USERDEFINED_MEMORY_86, 4=DEM_DTC_ORIGIN_USERDEFINED_MEMORY_87, 4=DEM_DTC_ORIGIN_USERDEFINED_MEMORY_88, 4=DEM_DTC_ORIGIN_USERDEFINED_MEMORY_89, 4=DEM_DTC_ORIGIN_USERDEFINED_MEMORY_8A, 4=DEM_DTC_ORIGIN_USERDEFINED_MEMORY_8B, 4=DEM_DTC_ORIGIN_USERDEFINED_MEMORY_8C, 4=DEM_DTC_ORIGIN_USERDEFINED_MEMORY_8D, 4=DEM_DTC_ORIGIN_USERDEFINED_MEMORY_8E, 4=DEM_DTC_ORIGIN_USERDEFINED_MEMORY_8F, 4=DEM_DTC_ORIGIN_USERDEFINED_MEMORY_90, 4=DEM_DTC_ORIGIN_USERDEFINED_MEMORY_91, 4=DEM_DTC_ORIGIN_USERDEFINED_MEMORY_92, 4=DEM_DTC_ORIGIN_USERDEFINED_MEMORY_93, 4=DEM_DTC_ORIGIN_USERDEFINED_MEMORY_94, 4=DEM_DTC_ORIGIN_USERDEFINED_MEMORY_95, 4=DEM_DTC_ORIGIN_USERDEFINED_MEMORY_96, 4=DEM_DTC_ORIGIN_USERDEFINED_MEMORY_97, 4=DEM_DTC_ORIGIN_USERDEFINED_MEMORY_98, 4=DEM_DTC_ORIGIN_USERDEFINED_MEMORY_99, 4=DEM_DTC_ORIGIN_USERDEFINED_MEMORY_9A, 4=DEM_DTC_ORIGIN_USERDEFINED_MEMORY_9B, 4=DEM_DTC_ORIGIN_USERDEFINED_MEMORY_9C, 4=DEM_DTC_ORIGIN_USERDEFINED_MEMORY_9D, 4=DEM_DTC_ORIGIN_USERDEFINED_MEMORY_9E, 4=DEM_DTC_ORIGIN_USERDEFINED_MEMORY_9F, 4=DEM_DTC_ORIGIN_USERDEFINED_MEMORY_A0, 4=DEM_DTC_ORIGIN_USERDEFINED_MEMORY_A1, 4=DEM_DTC_ORIGIN_USERDEFINED_MEMORY_A2, 4=DEM_DTC_ORIGIN_USERDEFINED_MEMORY_A3, 4=DEM_DTC_ORIGIN_USERDEFINED_MEMORY_A4, 4=DEM_DTC_ORIGIN_USERDEFINED_MEMORY_A5, 4=DEM_DTC_ORIGIN_USERDEFINED_MEMORY_A6, 4=DEM_DTC_ORIGIN_USERDEFINED_MEMORY_A7, 4=DEM_DTC_ORIGIN_USERDEFINED_MEMORY_A8, 4=DEM_DTC_ORIGIN_USERDEFINED_MEMORY_A9, 4=DEM_DTC_ORIGIN_USERDEFINED_MEMORY_AA, 4=DEM_DTC_ORIGIN_USERDEFINED_MEMORY_AB, 4=DEM_DTC_ORIGIN_USERDEFINED_MEMORY_AC, 4=DEM_DTC_ORIGIN_USERDEFINED_MEMORY_AD, 4=DEM_DTC_ORIGIN_USERDEFINED_MEMORY_AE, 4=DEM_DTC_ORIGIN_USERDEFINED_MEMORY_AF, 4=DEM_DTC_ORIGIN_USERDEFINED_MEMORY_B0, 4=DEM_DTC_ORIGIN_USERDEFINED_MEMORY_B1, 4=DEM_DTC_ORIGIN_USERDEFINED_MEMORY_B2, 4=DEM_DTC_ORIGIN_USERDEFINED_MEMORY_B3, 4=DEM_DTC_ORIGIN_USERDEFINED_MEMORY_B4, 4=DEM_DTC_ORIGIN_USERDEFINED_MEMORY_B5, 4=DEM_DTC_ORIGIN_USERDEFINED_MEMORY_B6, 4=DEM_DTC_ORIGIN_USERDEFINED_MEMORY_B7, 4=DEM_DTC_ORIGIN_USERDEFINED_MEMORY_B8, 4=DEM_DTC_ORIGIN_USERDEFINED_MEMORY_B9, 4=DEM_DTC_ORIGIN_USERDEFINED_MEMORY_BA, 4=DEM_DTC_ORIGIN_USERDEFINED_MEMORY_BB, 4=DEM_DTC_ORIGIN_USERDEFINED_MEMORY_BC, 4=DEM_DTC_ORIGIN_USERDEFINED_MEMORY_BD, 4=DEM_DTC_ORIGIN_USERDEFINED_MEMORY_BE, 4=DEM_DTC_ORIGIN_USERDEFINED_MEMORY_BF, 4=DEM_DTC_ORIGIN_USERDEFINED_MEMORY_C0, 4=DEM_DTC_ORIGIN_USERDEFINED_MEMORY_C1, 4=DEM_DTC_ORIGIN_USERDEFINED_MEMORY_C2, 4=DEM_DTC_ORIGIN_USERDEFINED_MEMORY_C3, 4=DEM_DTC_ORIGIN_USERDEFINED_MEMORY_C4, 4=DEM_DTC_ORIGIN_USERDEFINED_MEMORY_C5, 4=DEM_DTC_ORIGIN_USERDEFINED_MEMORY_C6, 4=DEM_DTC_ORIGIN_USERDEFINED_MEMORY_C7, 4=DEM_DTC_ORIGIN_USERDEFINED_MEMORY_C8, 4=DEM_DTC_ORIGIN_USERDEFINED_MEMORY_C9, 4=DEM_DTC_ORIGIN_USERDEFINED_MEMORY_CA, 4=DEM_DTC_ORIGIN_USERDEFINED_MEMORY_CB, 4=DEM_DTC_ORIGIN_USERDEFINED_MEMORY_CC, 4=DEM_DTC_ORIGIN_USERDEFINED_MEMORY_CD, 4=DEM_DTC_ORIGIN_USERDEFINED_MEMORY_CE, 4=DEM_DTC_ORIGIN_USERDEFINED_MEMORY_CF, 4=DEM_DTC_ORIGIN_USERDEFINED_MEMORY_D0, 4=DEM_DTC_ORIGIN_USERDEFINED_MEMORY_D1, 4=DEM_DTC_ORIGIN_USERDEFINED_MEMORY_D2, 4=DEM_DTC_ORIGIN_USERDEFINED_MEMORY_D3, 4=DEM_DTC_ORIGIN_USERDEFINED_MEMORY_D4, 4=DEM_DTC_ORIGIN_USERDEFINED_MEMORY_D5, 4=DEM_DTC_ORIGIN_USERDEFINED_MEMORY_D6, 4=DEM_DTC_ORIGIN_USERDEFINED_MEMORY_D7, 4=DEM_DTC_ORIGIN_USERDEFINED_MEMORY_D8, 4=DEM_DTC_ORIGIN_USERDEFINED_MEMORY_D9, 4=DEM_DTC_ORIGIN_USERDEFINED_MEMORY_DA, 4=DEM_DTC_ORIGIN_USERDEFINED_MEMORY_DB, 4=DEM_DTC_ORIGIN_USERDEFINED_MEMORY_DC, 4=DEM_DTC_ORIGIN_USERDEFINED_MEMORY_DD, 4=DEM_DTC_ORIGIN_USERDEFINED_MEMORY_DE, 4=DEM_DTC_ORIGIN_USERDEFINED_MEMORY_DF, 4=DEM_DTC_ORIGIN_USERDEFINED_MEMORY_E0, 4=DEM_DTC_ORIGIN_USERDEFINED_MEMORY_E1, 4=DEM_DTC_ORIGIN_USERDEFINED_MEMORY_E2, 4=DEM_DTC_ORIGIN_USERDEFINED_MEMORY_E3, 4=DEM_DTC_ORIGIN_USERDEFINED_MEMORY_E4, 4=DEM_DTC_ORIGIN_USERDEFINED_MEMORY_E5, 4=DEM_DTC_ORIGIN_USERDEFINED_MEMORY_E6, 4=DEM_DTC_ORIGIN_USERDEFINED_MEMORY_E7, 4=DEM_DTC_ORIGIN_USERDEFINED_MEMORY_E8, 4=DEM_DTC_ORIGIN_USERDEFINED_MEMORY_E9, 4=DEM_DTC_ORIGIN_USERDEFINED_MEMORY_EA, 4=DEM_DTC_ORIGIN_USERDEFINED_MEMORY_EB, 4=DEM_DTC_ORIGIN_USERDEFINED_MEMORY_EC, 4=DEM_DTC_ORIGIN_USERDEFINED_MEMORY_ED, 4=DEM_DTC_ORIGIN_USERDEFINED_MEMORY_EE, 4=DEM_DTC_ORIGIN_USERDEFINED_MEMORY_EF, 4=DEM_DTC_ORIGIN_USERDEFINED_MEMORY_F0, 4=DEM_DTC_ORIGIN_USERDEFINED_MEMORY_F1, 4=DEM_DTC_ORIGIN_USERDEFINED_MEMORY_F2, 4=DEM_DTC_ORIGIN_USERDEFINED_MEMORY_F3, 4=DEM_DTC_ORIGIN_USERDEFINED_MEMORY_F4, 4=DEM_DTC_ORIGIN_USERDEFINED_MEMORY_F5, 4=DEM_DTC_ORIGIN_USERDEFINED_MEMORY_F6, 4=DEM_DTC_ORIGIN_USERDEFINED_MEMORY_F7, 4=DEM_DTC_ORIGIN_USERDEFINED_MEMORY_F8, 4=DEM_DTC_ORIGIN_USERDEFINED_MEMORY_F9, 4=DEM_DTC_ORIGIN_USERDEFINED_MEMORY_FA, 4=DEM_DTC_ORIGIN_USERDEFINED_MEMORY_FB, 4=DEM_DTC_ORIGIN_USERDEFINED_MEMORY_FC, 4=DEM_DTC_ORIGIN_USERDEFINED_MEMORY_FD, 4=DEM_DTC_ORIGIN_USERDEFINED_MEMORY_FE, 4=DEM_DTC_ORIGIN_USERDEFINED_MEMORY_FF}, implementation-data-type=uint8
    Dem_DTCFormatType: compu {0=DEM_DTC_FORMAT_OBD, 1=DEM_DTC_FORMAT_UDS, 2=DEM_DTC_FORMAT_J1939}, implementation-data-type=uint8
    Dem_OperationCycleStateType: compu {0=DEM_CYCLE_STATE_START, 1=DEM_CYCLE_STATE_END}, implementation-data-type=uint8
    Dem_IndicatorStatusType: compu {0=DEM_INDICATOR_OFF, 1=DEM_INDICATOR_CONTINUOUS, 2=DEM_INDICATOR_BLINKING, 3=DEM_INDICATOR_BLINK_CONT, 4=DEM_INDICATOR_SLOW_FLASH, 5=DEM_INDICATOR_FAST_FLASH, 6=DEM_INDICATOR_ON_DEMAND, 7=DEM_INDICATOR_SHORT}, implementation-data-type=uint8
    Dem_DTCKindType: compu {1=DEM_DTC_KIND_ALL_DTCS, 2=DEM_DTC_KIND_EMISSION_REL_DTCS}, implementation-data-type=uint8
    Dem_IumprDenomCondIdType: compu {1=DEM_IUMPR_GENERAL_DENOMINATOR, 2=DEM_IUMPR_DEN_COND_COLDSTART, 3=DEM_IUMPR_DEN_COND_EVAP, 4=DEM_IUMPR_DEN_COND_500MI}, implementation-data-type=uint8
    Dem_IumprDenomCondStatusType: compu {0=DEM_IUMPR_DEN_STATUS_NOT_REACHED, 1=DEM_IUMPR_DEN_STATUS_REACHED, 2=DEM_IUMPR_DEN_STATUS_INHIBITED}, implementation-data-type=uint8
    Dem_DebounceResetStatusType: compu {0=DEM_DEBOUNCE_STATUS_FREEZE, 1=DEM_DEBOUNCE_STATUS_RESET}, implementation-data-type=uint8
    Dem_DebouncingStateType: compu {1=DEM_TEMPORARILY_DEFECTIVE, 2=DEM_FINALLY_DEFECTIVE, 4=DEM_TEMPORARILY_HEALED, 8=DEM_TEST_COMPLETE, 16=DEM_DTR_UPDATE}, implementation-data-type=uint8
package /MICROSAR/Dem_swc/Interfaces
  10 x client server interface, all with is-service=true, service-kind=DIAGNOSTIC-EVENT-MANAGER:
    CddIf
      operation ClearDTC: possible-error=[CddIf/DEM_CLEAR_WRONG_DTC, CddIf/DEM_CLEAR_WRONG_DTCORIGIN, CddIf/DEM_CLEAR_FAILED, CddIf/DEM_CLEAR_PENDING, CddIf/DEM_CLEAR_BUSY, CddIf/DEM_CLEAR_MEMORY_ERROR]
        arg DTC: type=uint32, direction=IN
        arg DTCFormat: type=Dem_DTCFormatType, direction=IN
        arg DTCOrigin: type=Dem_DTCOriginType, direction=IN
      6 x error:
        DEM_CLEAR_WRONG_DTC: error-code=1
        DEM_CLEAR_WRONG_DTCORIGIN: error-code=2
        DEM_CLEAR_FAILED: error-code=3
        DEM_CLEAR_PENDING: error-code=4
        DEM_CLEAR_BUSY: error-code=5
        DEM_CLEAR_MEMORY_ERROR: error-code=6
    DemServices
      operation GetPostRunRequested: possible-error=DemServices/E_NOT_OK
        arg IsRequested: type=boolean, direction=OUT
      operation GetDTCStatusAvailabilityMask: possible-error=DemServices/E_NOT_OK
        arg DTCStatusMask: type=uint8, direction=OUT
      error E_NOT_OK: error-code=1
    GeneralDiagnosticInfo
      9 x operation:
        GetEventStatus: possible-error=GeneralDiagnosticInfo/E_NOT_OK
          arg EventId: type=Dem_EventIdType, direction=IN
          arg EventStatusExtended: type=Dem_EventStatusExtendedType, direction=OUT
        GetEventFailed: possible-error=GeneralDiagnosticInfo/E_NOT_OK
          arg EventId: type=Dem_EventIdType, direction=IN
          arg EventFailed: type=boolean, direction=OUT
        GetEventTested: possible-error=GeneralDiagnosticInfo/E_NOT_OK
          arg EventId: type=Dem_EventIdType, direction=IN
          arg EventTested: type=boolean, direction=OUT
        GetDTCOfEvent: possible-error=[GeneralDiagnosticInfo/E_NOT_OK, GeneralDiagnosticInfo/DEM_E_NO_DTC_AVAILABLE]
          arg EventId: type=Dem_EventIdType, direction=IN
          arg DTCFormat: type=Dem_DTCFormatType, direction=IN
          arg DTCOfEvent: type=uint32, direction=OUT
        GetFaultDetectionCounter: possible-error=[GeneralDiagnosticInfo/E_NOT_OK, GeneralDiagnosticInfo/DEM_E_NO_FDC_AVAILABLE]
          arg EventId: type=Dem_EventIdType, direction=IN
          arg FaultDetectionCounter: type=sint8, direction=OUT
        GetEventFreezeFrameData: possible-error=[GeneralDiagnosticInfo/E_NOT_OK, GeneralDiagnosticInfo/DEM_E_NODATAAVAILABLE, GeneralDiagnosticInfo/DEM_E_WRONG_RECORDNUMBER, GeneralDiagnosticInfo/DEM_E_WRONG_DIDNUMBER]
          5 x arg:
            EventId: type=Dem_EventIdType, direction=IN
            RecordNumber: type=uint8, direction=IN
            ReportTotalRecord: type=boolean, direction=IN
            DataId: type=uint16, direction=IN
            DestBuffer: type=Dem_MaxDataValueType, direction=OUT
        GetEventExtendedDataRecord: possible-error=[GeneralDiagnosticInfo/E_NOT_OK, GeneralDiagnosticInfo/DEM_E_NODATAAVAILABLE, GeneralDiagnosticInfo/DEM_E_WRONG_RECORDNUMBER]
          arg EventId: type=Dem_EventIdType, direction=IN
          arg RecordNumber: type=uint8, direction=IN
          arg DestBuffer: type=Dem_MaxDataValueType, direction=OUT
        GetEventEnableCondition: possible-error=GeneralDiagnosticInfo/E_NOT_OK
          arg EventId: type=Dem_EventIdType, direction=IN
          arg ConditionFullfilled: type=boolean, direction=OUT
        GetDebouncingOfEvent: possible-error=GeneralDiagnosticInfo/E_NOT_OK
          arg EventId: type=Dem_EventIdType, direction=IN
          arg DebouncingState: type=Dem_DebouncingStateType, direction=OUT
      6 x error:
        E_NOT_OK: error-code=1
        DEM_E_NO_DTC_AVAILABLE: error-code=2
        DEM_E_NO_FDC_AVAILABLE: error-code=3
        DEM_E_NODATAAVAILABLE: error-code=48
        DEM_E_WRONG_RECORDNUMBER: error-code=49
        DEM_E_WRONG_DIDNUMBER: error-code=50
    DiagnosticInfo
      9 x operation:
        GetEventStatus: possible-error=DiagnosticInfo/E_NOT_OK
          arg EventStatusExtended: type=Dem_EventStatusExtendedType, direction=OUT
        GetEventFailed: possible-error=DiagnosticInfo/E_NOT_OK
          arg EventFailed: type=boolean, direction=OUT
        GetEventTested: possible-error=DiagnosticInfo/E_NOT_OK
          arg EventTested: type=boolean, direction=OUT
        GetDTCOfEvent: possible-error=[DiagnosticInfo/E_NOT_OK, DiagnosticInfo/DEM_E_NO_DTC_AVAILABLE]
          arg DTCFormat: type=Dem_DTCFormatType, direction=IN
          arg DTCOfEvent: type=uint32, direction=OUT
        GetFaultDetectionCounter: possible-error=[DiagnosticInfo/E_NOT_OK, DiagnosticInfo/DEM_E_NO_FDC_AVAILABLE]
          arg FaultDetectionCounter: type=sint8, direction=OUT
        GetEventFreezeFrameData: possible-error=[DiagnosticInfo/E_NOT_OK, DiagnosticInfo/DEM_E_NODATAAVAILABLE, DiagnosticInfo/DEM_E_WRONG_RECORDNUMBER, DiagnosticInfo/DEM_E_WRONG_DIDNUMBER]
          4 x arg:
            RecordNumber: type=uint8, direction=IN
            ReportTotalRecord: type=boolean, direction=IN
            DataId: type=uint16, direction=IN
            DestBuffer: type=Dem_MaxDataValueType, direction=OUT
        GetEventExtendedDataRecord: possible-error=[DiagnosticInfo/E_NOT_OK, DiagnosticInfo/DEM_E_NODATAAVAILABLE, DiagnosticInfo/DEM_E_WRONG_RECORDNUMBER]
          arg RecordNumber: type=uint8, direction=IN
          arg DestBuffer: type=Dem_MaxDataValueType, direction=OUT
        GetEventEnableCondition: possible-error=DiagnosticInfo/E_NOT_OK
          arg ConditionFullfilled: type=boolean, direction=OUT
        GetDebouncingOfEvent: possible-error=DiagnosticInfo/E_NOT_OK
          arg DebouncingState: type=Dem_DebouncingStateType, direction=OUT
      6 x error:
        E_NOT_OK: error-code=1
        DEM_E_NO_DTC_AVAILABLE: error-code=2
        DEM_E_NO_FDC_AVAILABLE: error-code=3
        DEM_E_NODATAAVAILABLE: error-code=48
        DEM_E_WRONG_RECORDNUMBER: error-code=49
        DEM_E_WRONG_DIDNUMBER: error-code=50
    DiagnosticMonitor
      10 x operation:
        SetEventStatus: possible-error=DiagnosticMonitor/E_NOT_OK
          arg EventStatus: type=Dem_EventStatusType, direction=IN
        ResetEventStatus: possible-error=DiagnosticMonitor/E_NOT_OK
        ResetEventDebounceStatus: possible-error=DiagnosticMonitor/E_NOT_OK
          arg DebounceResetStatus: type=Dem_DebounceResetStatusType, direction=IN
        GetEventStatus: possible-error=DiagnosticMonitor/E_NOT_OK
          arg EventStatusExtended: type=Dem_EventStatusExtendedType, direction=OUT
        GetEventFailed: possible-error=DiagnosticMonitor/E_NOT_OK
          arg EventFailed: type=boolean, direction=OUT
        GetEventTested: possible-error=DiagnosticMonitor/E_NOT_OK
          arg EventTested: type=boolean, direction=OUT
        GetDTCOfEvent: possible-error=[DiagnosticMonitor/E_NOT_OK, DiagnosticMonitor/DEM_E_NO_DTC_AVAILABLE]
          arg DTCFormat: type=Dem_DTCFormatType, direction=IN
          arg DTCOfEvent: type=uint32, direction=OUT
        GetFaultDetectionCounter: possible-error=[DiagnosticMonitor/E_NOT_OK, DiagnosticMonitor/DEM_E_NO_FDC_AVAILABLE]
          arg FaultDetectionCounter: type=sint8, direction=OUT
        GetEventFreezeFrameData: possible-error=[DiagnosticMonitor/E_NOT_OK, DiagnosticMonitor/DEM_E_NODATAAVAILABLE, DiagnosticMonitor/DEM_E_WRONG_RECORDNUMBER, DiagnosticMonitor/DEM_E_WRONG_DIDNUMBER]
          4 x arg:
            RecordNumber: type=uint8, direction=IN
            ReportTotalRecord: type=boolean, direction=IN
            DataId: type=uint16, direction=IN
            DestBuffer: type=Dem_MaxDataValueType, direction=OUT
        GetEventExtendedDataRecord: possible-error=[DiagnosticMonitor/E_NOT_OK, DiagnosticMonitor/DEM_E_NODATAAVAILABLE, DiagnosticMonitor/DEM_E_WRONG_RECORDNUMBER]
          arg RecordNumber: type=uint8, direction=IN
          arg DestBuffer: type=Dem_MaxDataValueType, direction=OUT
      6 x error:
        E_NOT_OK: error-code=1
        DEM_E_NO_DTC_AVAILABLE: error-code=2
        DEM_E_NO_FDC_AVAILABLE: error-code=3
        DEM_E_NODATAAVAILABLE: error-code=48
        DEM_E_WRONG_RECORDNUMBER: error-code=49
        DEM_E_WRONG_DIDNUMBER: error-code=50
    DcmIf
      5 x operation:
        DcmClearDTC: possible-error=[DcmIf/DEM_CLEAR_WRONG_DTC, DcmIf/DEM_CLEAR_WRONG_DTCORIGIN, DcmIf/DEM_CLEAR_FAILED, DcmIf/DEM_CLEAR_PENDING, DcmIf/DEM_CLEAR_BUSY, DcmIf/DEM_CLEAR_MEMORY_ERROR]
          arg DTC: type=uint32, direction=IN
          arg DTCFormat: type=Dem_DTCFormatType, direction=IN
          arg DTCOrigin: type=Dem_DTCOriginType, direction=IN
        DcmGetNextFilteredDTCAndFDC: possible-error=DEM_FILTERED_NO_MATCHING_DTC
          arg DTC: type=uint32, direction=OUT
          arg DTCFaultDetectionCounter: type=sint8, direction=OUT
        DcmEnableDTCSetting: possible-error=[DEM_CONTROL_DTC_SETTING_N_OK, DEM_CONTROL_DTC_WRONG_DTCGROUP]
          arg DTCGroup: type=Dem_DTCGroupType, direction=IN
          arg DTCKind: type=Dem_DTCKindType, direction=IN
        DcmGetFreezeFrameDataByDTC: possible-error=[DEM_GET_FFDATABYDTC_WRONG_DTC, DEM_GET_FFDATABYDTC_WRONG_DTCORIGIN, DEM_GET_FFDATABYDTC_WRONG_RECORDNUMBER, DEM_GET_FFDATABYDTC_WRONG_BUFFERSIZE, DEM_GET_FFDATABYDTC_PENDING]
          5 x arg:
            DTC: type=uint32, direction=IN
            DTCOrigin: type=Dem_DTCOriginType, direction=IN
            RecordNumber: type=uint8, direction=IN
            DestBuffer: type=uint8, direction=OUT
            BufSize: type=uint16, direction=INOUT
        DcmGetExtendedDataRecordByDTC: possible-error=[DEM_RECORD_WRONG_DTC, DEM_RECORD_WRONG_DTCORIGIN, DEM_RECORD_WRONG_NUMBER, DEM_RECORD_WRONG_BUFFERSIZE, DEM_RECORD_PENDING]
          5 x arg:
            DTC: type=uint32, direction=IN
            DTCOrigin: type=Dem_DTCOriginType, direction=IN
            ExtendedDataNumber: type=uint8, direction=IN
            DestBuffer: type=uint8, direction=OUT
            BufSize: type=uint16, direction=INOUT
      19 x error:
        DEM_CLEAR_WRONG_DTC: error-code=1
        DEM_CONTROL_DTC_SETTING_N_OK: error-code=1
        DEM_FILTERED_NO_MATCHING_DTC: error-code=1
        DEM_GET_FFDATABYDTC_WRONG_DTC: error-code=1
        DEM_RECORD_WRONG_DTC: error-code=1
        DEM_CLEAR_WRONG_DTCORIGIN: error-code=2
        DEM_CONTROL_DTC_WRONG_DTCGROUP: error-code=2
        DEM_GET_FFDATABYDTC_WRONG_DTCORIGIN: error-code=2
        DEM_RECORD_WRONG_DTCORIGIN: error-code=2
        DEM_CLEAR_FAILED: error-code=3
        DEM_GET_FFDATABYDTC_WRONG_RECORDNUMBER: error-code=3
        DEM_RECORD_WRONG_NUMBER: error-code=3
        DEM_CLEAR_PENDING: error-code=4
        DEM_GET_FFDATABYDTC_WRONG_BUFFERSIZE: error-code=4
        DEM_RECORD_WRONG_BUFFERSIZE: error-code=4
        DEM_CLEAR_BUSY: error-code=5
        DEM_GET_FFDATABYDTC_PENDING: error-code=5
        DEM_RECORD_PENDING: error-code=5
        DEM_CLEAR_MEMORY_ERROR: error-code=6
    OperationCycle
      operation SetOperationCycleState: possible-error=OperationCycle/E_NOT_OK
        arg CycleState: type=Dem_OperationCycleStateType, direction=IN
      error E_NOT_OK: error-code=1
    GeneralCallbackEventStatusChange
      operation EventStatusChanged
        arg EventId: type=Dem_EventIdType, direction=IN
        arg EventStatusOld: type=Dem_EventStatusExtendedType, direction=IN
        arg EventStatusNew: type=Dem_EventStatusExtendedType, direction=IN
    EvMemOverflowIndication
      operation GetEventMemoryOverflow: possible-error=EvMemOverflowIndication/E_NOT_OK
        arg OverflowIndication: type=boolean, direction=OUT
      operation GetNumberOfEventMemoryEntries: possible-error=EvMemOverflowIndication/E_NOT_OK
        arg NumberOfEventMemoryEntries: type=uint8, direction=OUT
      error E_NOT_OK: error-code=1
    EnableCondition
      operation SetEnableCondition: possible-error=EnableCondition/E_NOT_OK
        arg ConditionFulfilled: type=boolean, direction=IN
      error E_NOT_OK: error-code=1
